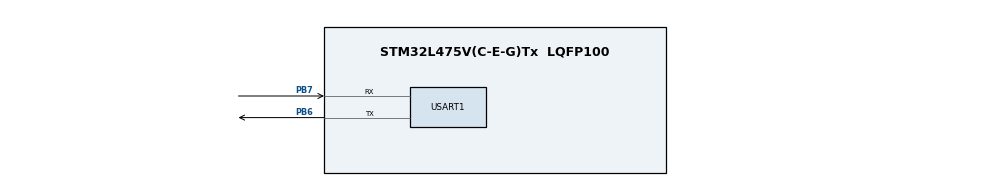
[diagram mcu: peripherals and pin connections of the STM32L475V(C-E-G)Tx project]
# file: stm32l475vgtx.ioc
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Mcu.Family=STM32L4
Mcu.Name=STM32L475V(C-E-G)Tx
Mcu.Package=LQFP100
NVIC.PriorityGroup=NVIC_PRIORITYGROUP_4
PB6.Mode=Asynchronous
PB6.Signal=USART1_TX
PB7.Mode=Asynchronous
PB7.Signal=USART1_RX
ProjectManager.HeapSize=0x200
ProjectManager.StackSize=0x400
ProjectManager.TargetToolchain=Makefile
RCC.HSE_VALUE=8000000
RCC.HSI_VALUE=16000000
RCC.LSE_VALUE=32768
RCC.MSI_VALUE=4000000
RCC.VCOOutputFreq_Value=32000000
USART1.VirtualMode-Asynchronous=VM_ASYNC
board=custom

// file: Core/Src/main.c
/* USER CODE BEGIN Header */
/**
  ******************************************************************************
  * @file           : main.c
  * @brief          : Main program body
  ******************************************************************************
  * @attention
  *
  * <h2><center>&copy; Copyright (c) 2022 STMicroelectronics.
  * All rights reserved.</center></h2>
  *
  * This software component is licensed by ST under BSD 3-Clause license,
  * the "License"; You may not use this file except in compliance with the
  * License. You may obtain a copy of the License at:
  *                        opensource.org/licenses/BSD-3-Clause
  *
  ******************************************************************************
  */
/* USER CODE END Header */
#include "main.h"

/* USER CODE BEGIN Includes */
#include <string.h>
/* USER CODE END Includes */

UART_HandleTypeDef huart1;

void SystemClock_Config(void);
static void MX_GPIO_Init(void);
static void MX_USART1_UART_Init(void);
/* USER CODE BEGIN PFP */
#include <stdio.h>
#if SYSTEM_SUPPORT_OS == 0
/** Overwrite printf when using MDK**/
int fputc(int ch, FILE *f)
{
	while((USART1->ISR&0X40)==0);
	USART1->RDR = (uint8_t) ch;
	return ch;
}

/** Overwrite printf when using GCC**/
int _write(int fd, char *ptr, int len)
{
  HAL_UART_Transmit(&huart1, (uint8_t*)ptr, len, 0xFFFF);
  return len;
}
#else
/** Overwrite printf when using MDK**/
int fputc(int ch, FILE *f)
{
    taskENTER_CRITICAL();
	while((USART1->SR&0X40)==0);
	USART1->DR = (uint8_t) ch;
    taskEXIT_CRITICAL();
	return ch;
}

/** Overwrite printf when using GCC**/
int _write(int fd, char *ptr, int len)
{
  taskENTER_CRITICAL();
  HAL_UART_Transmit(&huart1, (uint8_t*)ptr, len, 0xFFFF);
  taskEXIT_CRITICAL();
  return len;
}
#endif
__STATIC_INLINE uint32_t LL_SYSTICK_IsActiveCounterFlag(void)
{
  //判断COUNTFLAG位是否为1，1则计数器已经递减到0了至少一次。读取该位后该位自动清零。
  return ((SysTick->CTRL & SysTick_CTRL_COUNTFLAG_Msk) == (SysTick_CTRL_COUNTFLAG_Msk));
}
uint32_t getCurrentMicros(void)
{
 /* Ensure COUNTFLAG is reset by reading SysTick control and status register */
 LL_SYSTICK_IsActiveCounterFlag();           //清除计数器"溢出"标志位
 uint32_t m = HAL_GetTick();
 const uint32_t tms = SysTick->LOAD + 1;
 __IO uint32_t u = tms - SysTick->VAL;
 if (LL_SYSTICK_IsActiveCounterFlag()) {
 m = HAL_GetTick();
 u = tms - SysTick->VAL;
  }
 return (m * 1000 + (u * 1000) / tms);
}
/* USER CODE END PFP */

/* USER CODE BEGIN 0 */
#include "test_data.h"
#include "calc_fn.h"
int infer(float* din)
{
    int res;
    float dout[10];
    uint32_t start = getCurrentMicros();
    calc_fn(din, dout);
    // printf("dout: %f %f %f %f %f %f %f %f %f %f\n", dout[0], dout[1], dout[2], dout[3], dout[4], dout[5], dout[6], dout[7], dout[8], dout[9]);
    argmax_f32(&res, dout, 10);
    uint32_t end = getCurrentMicros();
    printf("Time elapsed: %f\n", (float)(end - start) / 1000000);
    return res;
}

void run() {
  const float* din;
    int res, err;
    err = 0;
    for (int n = 0; n < TEST_DATA_NUM; n++)
    {
        din = &test_x[n][0];
        res = infer((float*)din);
        err += res != test_y[n];
        printf("[INF] TEST: %d, OUT: %d, GT: %d %s\n", n, res, test_y[n],(res==test_y[n])?"":"******");
    }
    printf("[INF] #error: %d, ACC: %.2f%%\n", err, 100.0-(float)err / (float)TEST_DATA_NUM * 100.0);
}

/* USER CODE END 0 */

int main(void)
{

  /* MCU Configuration--------------------------------------------------------*/

  /* Reset of all peripherals, Initializes the Flash interface and the Systick. */
  HAL_Init();

  /* Configure the system clock */
  SystemClock_Config();

  /* Initialize all configured peripherals */
  MX_GPIO_Init();
  MX_USART1_UART_Init();
  /* USER CODE BEGIN 2 */
  char * pData = "helloworld\n";
  /* USER CODE END 2 */

  /* Infinite loop */
  /* USER CODE BEGIN WHILE */
  while (1)
  {
    HAL_UART_Transmit(&huart1, (uint8_t*)pData, strlen(pData), 100);
    run();
    HAL_Delay(1000);
    /* USER CODE END WHILE */

  }
}

void SystemClock_Config(void)
{
  RCC_OscInitTypeDef RCC_OscInitStruct = {0};
  RCC_ClkInitTypeDef RCC_ClkInitStruct = {0};

  /** Configure the main internal regulator output voltage
  */
  if (HAL_PWREx_ControlVoltageScaling(PWR_REGULATOR_VOLTAGE_SCALE1) != HAL_OK)
  {
    Error_Handler();
  }
  /** Initializes the RCC Oscillators according to the specified parameters
  * in the RCC_OscInitTypeDef structure.
  */
  RCC_OscInitStruct.OscillatorType = RCC_OSCILLATORTYPE_MSI;
  RCC_OscInitStruct.MSIState = RCC_MSI_ON;
  RCC_OscInitStruct.MSICalibrationValue = 0;
  RCC_OscInitStruct.MSIClockRange = RCC_MSIRANGE_6;
  RCC_OscInitStruct.PLL.PLLState = RCC_PLL_NONE;
  if (HAL_RCC_OscConfig(&RCC_OscInitStruct) != HAL_OK)
  {
    Error_Handler();
  }
  /** Initializes the CPU, AHB and APB buses clocks
  */
  RCC_ClkInitStruct.ClockType = RCC_CLOCKTYPE_HCLK|RCC_CLOCKTYPE_SYSCLK
                              |RCC_CLOCKTYPE_PCLK1|RCC_CLOCKTYPE_PCLK2;
  RCC_ClkInitStruct.SYSCLKSource = RCC_SYSCLKSOURCE_MSI;
  RCC_ClkInitStruct.AHBCLKDivider = RCC_SYSCLK_DIV1;
  RCC_ClkInitStruct.APB1CLKDivider = RCC_HCLK_DIV1;
  RCC_ClkInitStruct.APB2CLKDivider = RCC_HCLK_DIV1;

  if (HAL_RCC_ClockConfig(&RCC_ClkInitStruct, FLASH_LATENCY_0) != HAL_OK)
  {
    Error_Handler();
  }
}

static void MX_USART1_UART_Init(void)
{

  huart1.Instance = USART1;
  huart1.Init.BaudRate = 115200;
  huart1.Init.WordLength = UART_WORDLENGTH_8B;
  huart1.Init.StopBits = UART_STOPBITS_1;
  huart1.Init.Parity = UART_PARITY_NONE;
  huart1.Init.Mode = UART_MODE_TX_RX;
  huart1.Init.HwFlowCtl = UART_HWCONTROL_NONE;
  huart1.Init.OverSampling = UART_OVERSAMPLING_16;
  huart1.Init.OneBitSampling = UART_ONE_BIT_SAMPLE_DISABLE;
  huart1.AdvancedInit.AdvFeatureInit = UART_ADVFEATURE_NO_INIT;
  if (HAL_UART_Init(&huart1) != HAL_OK)
  {
    Error_Handler();
  }

}

static void MX_GPIO_Init(void)
{

  /* GPIO Ports Clock Enable */
  __HAL_RCC_GPIOB_CLK_ENABLE();

}

void Error_Handler(void)
{
  __disable_irq();
  while (1)
  {
  }
}

/************************ (C) COPYRIGHT STMicroelectronics *****END OF FILE****/
